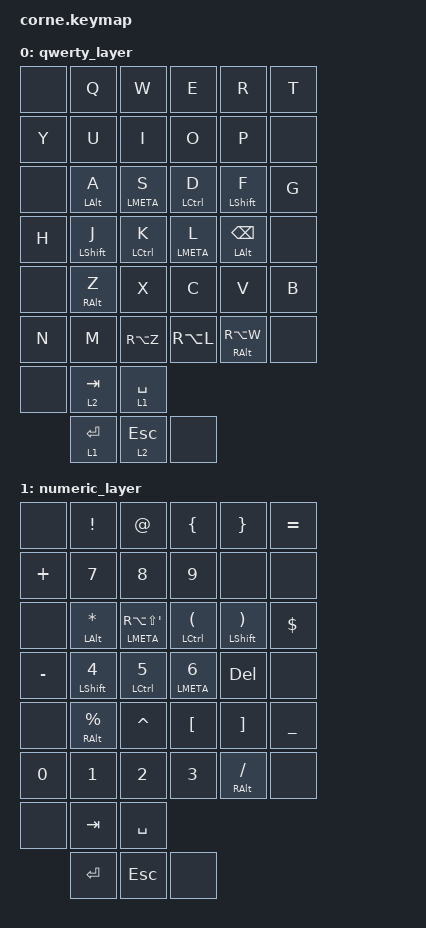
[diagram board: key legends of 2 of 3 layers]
#include <behaviors.dtsi>
#include <dt-bindings/zmk/keys.h>
#include <dt-bindings/zmk/bt.h>

&lt {
  tapping-term-ms = <200>;
  quick-tap-ms = <150>;
  flavor = "balanced";
};
&mt {
  tapping-term-ms = <200>;
  quick-tap-ms = <150>;
  flavor = "balanced";
};

/ {
  keymap {
    compatible = "zmk,keymap";
    qwerty_layer {
      bindings = <

//  |===========|=============|=============|=============|===============|
//  | Q         | W           | E           | R           | T             |
&none &kp Q       &kp W         &kp E         &kp R         &kp T
//  |-----------|-------------|-------------|-------------|---------------|
//  | Y         | U           | I           | O           | P             |
      &kp Y       &kp U         &kp I         &kp O         &kp P         &none
//  |===========|=============|=============|=============|===============|
//  | A         | S           | D           | F           | G             |
&none &mt LALT A  &mt LMETA S   &mt LCTRL D   &mt LSHFT F   &kp G
//  |-----------|-------------|-------------|-------------|---------------|
//  | H         | J           | K           | L           | BACKSPACE     |
      &kp H       &mt LSHFT J   &mt LCTRL K   &mt LMETA L   &mt LALT BSPC &none
//  |===========|=============|=============|=============|===============|
//  | Z         | X           | C           | V           | B             |
&none &mt RALT Z  &kp X         &kp C         &kp V         &kp B
//  |-----------|-------------|-------------|-------------|---------------|
//  | N         | M           | Æ           | Ø           | Å             |
      &kp N       &kp M         &kp RA(Z)     &kp RA(L)     &mt RALT RA(W) &none
//  |===========|=============|=============|=============|===============|

//  |===========|=============|
//  | TAB       | SPACE       |
&none &lt 2 TAB   &lt 1 SPACE
//  |-----------|-------------|
//  | ENTER     | ESCAPE      |
      &lt 1 ENTER &lt 2 ESC   &none
//  |===========|=============|
      >;
    };
    numeric_layer {
      bindings = <
//  |===============|===============|===============|=================|===============|
//  | !             | @             | {             | }               | =             |
&none &kp EXCL        &kp AT          &kp LBRC        &kp RBRC          &kp EQUAL
//  |---------------|---------------|---------------|-----------------|---------------|
//  | +             | 7             | 8             | 9               | SYSTEM_LAYER  |
      &kp PLUS        &kp N7          &kp N8          &kp N9            &none         &none
//  |===============|===============|===============|=================|===============|
//  | *             | "             | (             | )               | $             |
&none &mt LALT STAR   &mt LMETA RA(LS(SQT)) &mt LCTRL LPAR  &mt LSHFT RPAR  &kp DLLR
//  |---------------|---------------|---------------|-----------------|---------------|
//  | -             | 4             | 5             | 6               | DEL           |
      &kp MINUS       &mt LSHFT N4    &mt LCTRL N5    &mt LMETA N6      &kp DEL       &none
//  |===============|===============|===============|=================|===============|
//  | %             | ^             | [             | ]               | _             |
&none &mt RALT PERCENT &kp CARET     &kp LBKT        &kp RBKT          &kp UNDER
//  |---------------|---------------|---------------|-----------------|---------------|
//  | 0             | 1             | 2             | 3               | /             |
      &kp 0           &kp N1          &kp N2          &kp N3            &mt RALT FSLH &none
//  |===============|===============|===============|=================|===============|

//  |===============|===============|
//  | TAB           | SPACE         |
&none &kp TAB         &kp SPACE
//  |---------------|---------------|
//  | ENTER         | ESCAPE        |
      &kp ENTER       &kp ESC       &none
//  |===============|===============|
      >;
    };
    navigation_layer {
      bindings = <
//  |===============|=================|===============|===============|===============|
//  | |             | §               | «             | »             | ?             |
&none &kp PIPE        &kp RA(LS(S))     &kp RA(LBKT)    &kp RA(RBKT)    &kp LS(MINUS)
//  |---------------|-----------------|---------------|---------------|---------------|
//  | HOME          | PGDN            | PGUP          | END           | SYSTEM_LAYER  |
      &kp HOME        &kp PG_DN         &kp PG_UP       &kp END         &none         &none
//  |===============|=================|===============|===============|===============|
//  | HASH          | '               | <             | >             | &             |
&none &mt LALT HASH   &mt LMETA SQT     &mt LCTRL LT    &mt LSHFT GT    &kp AMPS
//  |---------------|-----------------|---------------|---------------|---------------|
//  | LEFT          | DOWN            | UP            | RIGHT         | INS           |
      &kp LEFT        &mt LSHFT DOWN    &mt LCTRL UP    &mt LALT RIGHT  &kp INS       &none
//  |===============|=================|===============|===============|===============|
//  | ¨             | ~               | `             | ´             | CAPS_WORD     |
&none &mt RALT DQT    &kp TILDE         &kp GRAVE       &kp RA(SQT)     &caps_word
//  |---------------|-----------------|---------------|---------------|---------------|
//  | ;             | :               | ,             | .             | \             |
//    &kp SEMI        &kp COLON         &kp COMMA       &kp DOT         &mt RALT BSLH &none
//  |===============|=================|===============|===============|===============|

//  |===============|===============|
//  | TAB           | SPACE         |
&none &kp TAB         &kp SPACE
//  |---------------|---------------|
//  | ENTER         | ESCAPE        |
      &kp ENTER       &kp ESC       &none
//  |===============|===============|
      >;
    };
  };
};
